# MCXN947_cm33_core0 register map
Vendor: nxp.com; File version: 1.0
CPU: CM33 r2p0, little endian, MPU, FPU, VTOR, 3 interrupt priority bits
Registers are 32-bit, read-write, reset 0x0 unless marked. A register's access mark holds for its fields unless they carry their own. Offsets are from the block's base; [hi:lo] are bit positions; {n}, {i} and the like mark numbered series; 'fields as' and 'values as' point back to an identical list.

## LPI2C0 — LPI2C
Base 0x40092800
Same registers: LPI2C1 0x40093800, LPI2C2 0x40094800, LPI2C3 0x40095800, LPI2C4 0x400B4800, LPI2C5 0x400B5800, LPI2C6 0x400B6800, LPI2C7 0x400B7800, LPI2C8 0x400B8800, LPI2C9 0x400B9800
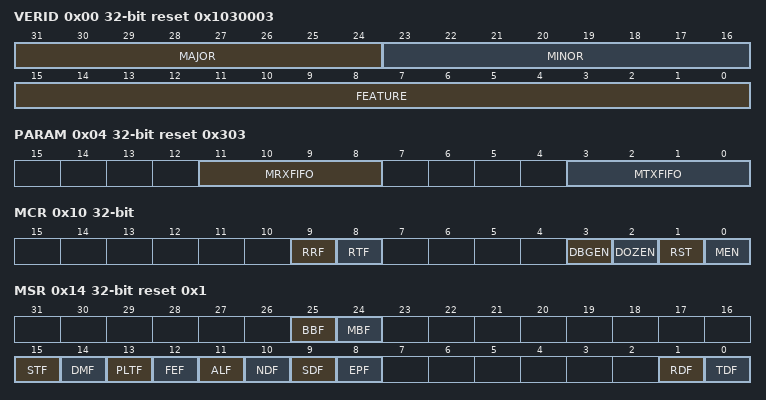
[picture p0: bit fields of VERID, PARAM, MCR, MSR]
0x00 VERID ro reset 0x1030003 — Version ID
  [31:24] MAJOR — Major Version Number
  [23:16] MINOR — Minor Version Number
  [15:0] FEATURE — Feature Specification Number
    2=MASTER_ONLY (Controller only, with standard feature set); 3=MASTER_AND_SLAVE (Controller and target, with standard feature set)
0x04 PARAM ro reset 0x303 — Parameter
  [11:8] MRXFIFO — Controller Receive FIFO Size
  [3:0] MTXFIFO — Controller Transmit FIFO Size
0x10 MCR — Controller Control
  [9] RRF — Reset Receive FIFO
    0=NO_EFFECT; 1=RESET (Receive FIFO is reset)
  [8] RTF — Reset Transmit FIFO
    0=NO_EFFECT; 1=RESET (Transmit FIFO is reset)
  [3] DBGEN — Debug Enable
    0=DISABLED (Controller is disabled in debug mode); 1=ENABLED (Controller is enabled in debug mode)
  [2] DOZEN — Doze mode enable
    0=ENABLED (Controller is enabled in doze mode); 1=DISABLED (Controller is disabled in doze mode)
  [1] RST — Software Reset
    0=NOT_RESET; 1=RESET
  [0] MEN — Controller Enable
    0=DISABLED; 1=ENABLED
0x14 MSR reset 0x1 — Controller Status
  [25] BBF ro — Bus Busy Flag
    0=IDLE; 1=BUSY
  [24] MBF ro — Controller Busy Flag
    0=IDLE; 1=BUSY
  [15] STF write-1-clears — START Flag
    0=NO_FLAG (START condition not detected.); 1=FLAG (START condition detected.)
  [14] DMF write-1-clears — Data Match Flag
    0=NO_FLAG (Have not received matching data); 1=FLAG (Have received matching data)
  [13] PLTF write-1-clears — Pin Low Timeout Flag
    0=NO_FLAG (Pin low timeout has not occurred or is disabled); 1=FLAG (Pin low timeout has occurred)
  [12] FEF write-1-clears — FIFO Error Flag
    0=NO_FLAG (No error); 1=FLAG (Controller sending or receiving data without a START condition)
  [11] ALF write-1-clears — Arbitration Lost Flag
    0=NO_FLAG (Controller has not lost arbitration); 1=FLAG (Controller has lost arbitration)
  [10] NDF write-1-clears — NACK Detect Flag
    0=NO_FLAG (Unexpected NACK was not detected); 1=FLAG (Unexpected NACK was detected)
  [9] SDF write-1-clears — STOP Detect Flag
    0=NO_FLAG (Controller has not generated a STOP condition); 1=FLAG (Controller has generated a STOP condition)
  [8] EPF write-1-clears — End Packet Flag
    0=NO_FLAG (Controller has not generated a STOP or Repeated START condition); 1=FLAG (Controller has generated a STOP or Repeated START condition)
  [1] RDF ro — Receive Data Flag
    0=DISABLED (Receive data is not ready); 1=ENABLED (Receive data is ready)
  [0] TDF ro — Transmit Data Flag
    0=DISABLED (Transmit data is not requested); 1=ENABLED (Transmit data is requested)
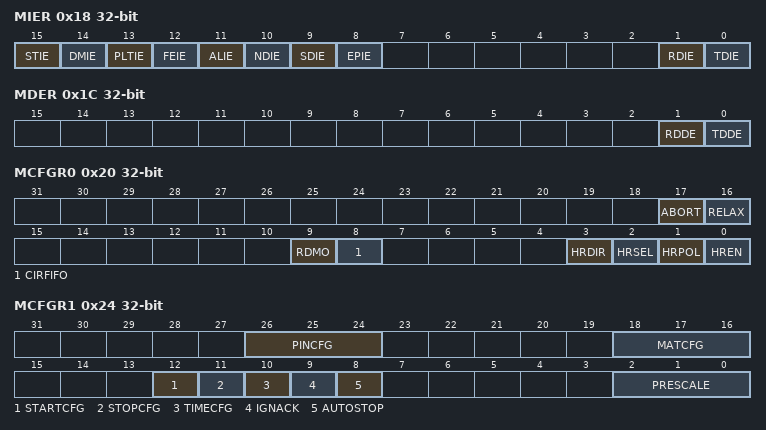
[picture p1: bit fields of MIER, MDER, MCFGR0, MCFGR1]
0x18 MIER — Controller Interrupt Enable
  [all] fields
    0=DISABLED; 1=ENABLED
  [15] STIE — START Interrupt Enable
  [14] DMIE — Data Match Interrupt Enable
  [13] PLTIE — Pin Low Timeout Interrupt Enable
  [12] FEIE — FIFO Error Interrupt Enable
  [11] ALIE — Arbitration Lost Interrupt Enable
  [10] NDIE — NACK Detect Interrupt Enable
  [9] SDIE — STOP Detect Interrupt Enable
  [8] EPIE — End Packet Interrupt Enable
  [1] RDIE — Receive Data Interrupt Enable
  [0] TDIE — Transmit Data Interrupt Enable
0x1C MDER — Controller DMA Enable
  [1] RDDE — Receive Data DMA Enable
    0=DISABLED (DMA request is disabled); 1=ENABLED (DMA request is enabled)
  [0] TDDE — Transmit Data DMA Enable
    values as RDDE
0x20 MCFGR0 — Controller Configuration 0
  [17] ABORT — Abort Transfer
    0=DISABLED (Normal transfer); 1=ENABLED (Abort existing transfer and do not start new transfer)
  [16] RELAX — Relaxed Mode
    0=NORMAL_TRANSFER; 1=RELAXED_TRANSFER
  [9] RDMO — Receive data match only
    0=DISABLED (Received data is stored in the receive FIFO); 1=ENABLED (Received data is discarded unless the Data Match Flag (MSR[DMF]) is 1.)
  [8] CIRFIFO — Circular FIFO enable
    0=DISABLED (Circular FIFO is disabled); 1=ENABLED (Circular FIFO is enabled)
  [3] HRDIR — Host request direction
    0=INPUT (HREQ pin is input (for LPI2C controller)); 1=OUTPUT (HREQ pin is output (for LPI2C target))
  [2] HRSEL — Host request select
    0=DISABLED (Host request input is pin HREQ); 1=ENABLED (Host request input is input trigger)
  [1] HRPOL — Host request polarity
    0=ACTIVE_LOW; 1=ACTIVE_HIGH
  [0] HREN — Host request enable
    0=DISABLED (Host request input is disabled); 1=ENABLED (Host request input is enabled)
0x24 MCFGR1 — Controller Configuration 1
  [26:24] PINCFG — Pin Configuration
    0=OPEN_DRAIN_2_PIN (Two-pin open drain mode); 1=OUTPUT_2_PIN_ONLY (Two-pin output only mode (ultra-fast mode)); 2=PUSH_PULL_2_PIN (Two-pin push-pull mode); 3=PUSH_PULL_4_PIN (Four-pin push-pull mode); 4=OPEN_DRAIN_2_PIN_W_LPI2C_SLAVE (Two-pin open drain mode with separate LPI2C target); 5=OUTPUT_2_PIN_ONLY_W_LPI2C_SLAVE (Two-pin output only mode (ultra-fast mode) with separate LPI2C target); 6=PUSH_PULL_2_PIN_W_LPI2C_SLAVE (Two-pin push-pull mode with separate LPI2C target); 7=PUSH_PULL_4_PIN_W_LPI2C_SLAVE (Four-pin push-pull mode (inverted outputs))
  [18:16] MATCFG — Match Configuration
    0=DISABLED (Match is disabled); 2=FIRST_DATA_WORD_EQUALS_MATCH0_OR_MATCH1 (Match is enabled (first data word equals MDMR[MATCH0] OR MDMR[MATCH1])); 3=ANY_DATA_WORD_EQUALS_MATCH0_OR_MATCH1 (Match is enabled (any data word equals MDMR[MATCH0] OR MDMR[MATCH1])); 4=FIRST_DATA_WORD_MATCH0_AND_SECOND_DATA_WORD_MATCH1 (Match is enabled (first data word equals MDMR[MATCH0] AND second data word equals MDMR[MATCH1)); 5=ANY_DATA_WORD_MATCH0_NEXT_DATA_WORD_MATCH1 (Match is enabled (any data word equals MDMR[MATCH0] AND next data word equals MDMR[MATCH1)); 6=FIRST_DATA_WORD_AND_MATCH1_EQUALS_MATCH0_AND_MATCH1 (Match is enabled (first data word AND MDMR[MATCH1] equals MDMR[MATCH0] AND MDMR[MATCH1])); 7=ANY_DATA_WORD_AND_MATCH1_EQUALS_MATCH0_AND_MATCH1 (Match is enabled (any data word AND MDMR[MATCH1] equals MDMR[MATCH0] AND MDMR[MATCH1]))
  [12] STARTCFG — START Configuration
    0=BOTH_I2C_AND_LPI2C_IDLE (MSR[STF] asserts on START condition provided both I2C bus and LPI2C controller are idle (that is, any non-repeated START condition initiated by any other controller on the bus but not the LPI2C controller).); 1=I2C_IDLE (MSR[STF] asserts on START condition provided I2C bus is idle (that is, any non-repeated START condition initiated by any controller on the bus including the LPI2C controller).)
  [11] STOPCFG — STOP Configuration
    0=ANY_STOP (MSR[SDF] asserts on any STOP condition generated by LPI2C controller.); 1=LAST_STOP (MSR[SDF] asserts on last STOP condition before LPI2C controller is idle (that is, the transmit FIFO is empty at the time of the STOP condition).)
  [10] TIMECFG — Timeout Configuration
    0=IF_SCL_LOW (MSR[PLTF] becomes 1 if SCL is low for longer than the configured timeout.); 1=IF_SCL_OR_SDA_LOW (MSR[PLTF] becomes 1 if either SCL or SDA is low for longer than the configured timeout.)
  [9] IGNACK — Ignore NACK
    0=DISABLED (No effect); 1=ENABLED (LPI2C controller treats a received NACK as if it (NACK) was an ACK and the NACK Detect Flag is never written 1.)
  [8] AUTOSTOP — Automatic STOP Generation
    0=DISABLED (No effect); 1=ENABLED (STOP condition is automatically generated when the transmit FIFO is empty and the LPI2C controller is busy)
  [2:0] PRESCALE — Prescaler
    0=DIVIDE_BY_1; 1=DIVIDE_BY_2; 2=DIVIDE_BY_4; 3=DIVIDE_BY_8; 4=DIVIDE_BY_16; 5=DIVIDE_BY_32; 6=DIVIDE_BY_64; 7=DIVIDE_BY_128
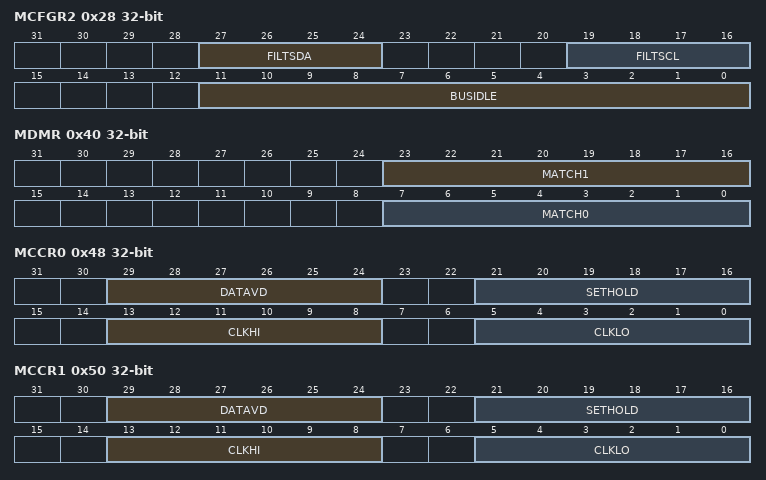
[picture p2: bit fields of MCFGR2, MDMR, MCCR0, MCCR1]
0x28 MCFGR2 — Controller Configuration 2
  [27:24] FILTSDA — Glitch Filter SDA
  [19:16] FILTSCL — Glitch Filter SCL
  [11:0] BUSIDLE — Bus Idle Timeout
0x2C MCFGR3 — Controller Configuration 3
  [19:8] PINLOW — Pin low timeout
0x40 MDMR — Controller Data Match
  [23:16] MATCH1 — Match 1 Value
  [7:0] MATCH0 — Match 0 Value
0x48 MCCR0 — Controller Clock Configuration 0
  [29:24] DATAVD — Data Valid Delay
  [21:16] SETHOLD — Setup Hold Delay
  [13:8] CLKHI — Clock High Period
  [5:0] CLKLO — Clock Low Period
0x50 MCCR1 — Controller Clock Configuration 1
  fields as MCCR0
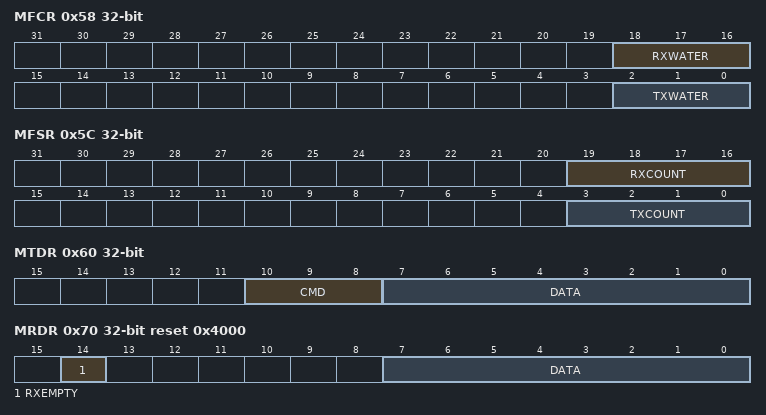
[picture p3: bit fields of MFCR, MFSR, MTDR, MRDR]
0x58 MFCR — Controller FIFO Control
  [18:16] RXWATER — Receive FIFO Watermark
  [2:0] TXWATER — Transmit FIFO Watermark
0x5C MFSR ro — Controller FIFO Status
  [19:16] RXCOUNT — Receive FIFO Count
  [3:0] TXCOUNT — Transmit FIFO Count
0x60 MTDR wo — Controller Transmit Data
  [10:8] CMD — Command Data
    0=TRANSMIT_DATA_7_THROUGH_0 (Transmit DATA[7:0]); 1=RECEIVE_DATA_7_THROUGH_0_PLUS_ONE (Receive (DATA[7:0] + 1) bytes); 2=GENERATE_STOP_CONDITION; 3=RECEIVE_AND_DISCARD_DATA_7_THROUGH_0_PLUS_ONE (Receive and discard (DATA[7:0] + 1) bytes); 4=GENERATE_START_AND_TRANSMIT_ADDRESS_IN_DATA_7_THROUGH_0 (Generate (repeated) START and transmit address in DATA[7:0]); 5=GENERATE_START_AND_TRANSMIT_ADDRESS_IN_DATA_7_THROUGH_0_EXPECT_NACK (Generate (repeated) START and transmit address in DATA[7:0]. This transfer expects a NACK to be returned.); 6=GENERATE_START_AND_TRANSMIT_ADDRESS_IN_DATA_7_THROUGH_0_USING_HIGH_SPEED_MODE (Generate (repeated) START and transmit address in DATA[7:0] using high-speed mode); 7=GENERATE_START_AND_TRANSMIT_ADDRESS_IN_DATA_7_THROUGH_0_USING_HIGH_SPEED_MODE_EXPECT_NACK (Generate (repeated) START and transmit address in DATA[7:0] using high-speed mode. This transfer expects a NACK to be returned.)
  [7:0] DATA — Transmit Data
0x70 MRDR ro reset 0x4000 — Controller Receive Data
  [14] RXEMPTY — Receive Empty
    0=NOT_EMPTY (Receive FIFO is not empty); 1=EMPTY (Receive FIFO is empty)
  [7:0] DATA — Receive Data
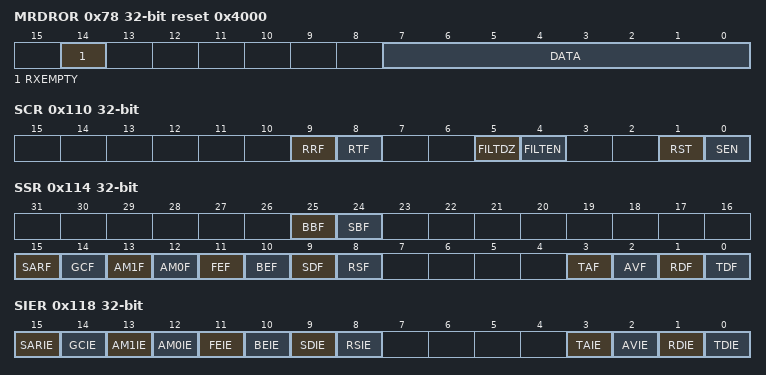
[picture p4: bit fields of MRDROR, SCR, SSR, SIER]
0x78 MRDROR ro reset 0x4000 — Controller Receive Data Read Only
  [14] RXEMPTY
    values as MRDR.RXEMPTY
  [7:0] DATA — Receive Data
0x110 SCR — Target Control
  [9] RRF — Reset Receive FIFO
    0=NO_EFFECT; 1=NOW_EMPTY (Receive Data Register is now empty.)
  [8] RTF — Reset transmit FIFO
    0=NO_EFFECT; 1=NOW_EMPTY (Transmit Data Register is now empty.)
  [5] FILTDZ — Filter doze enable
    0=FILTER_ENABLED (Filter remains enabled in Doze mode); 1=FILTER_DISABLED (Filter is disabled in Doze mode)
  [4] FILTEN — Filter enable
    0=DISABLE (Disable digital filter and output delay counter for target mode); 1=ENABLE (Enable digital filter and output delay counter for target mode)
  [1] RST — Software reset
    0=NOT_RESET (Target mode logic is not reset); 1=RESET (Target mode logic is reset)
  [0] SEN — Target Enable
    0=DISABLED (I2C Target mode is disabled); 1=ENABLED (I2C Target mode is enabled)
0x114 SSR — Target Status
  [25] BBF ro — Bus busy flag
    0=IDLE; 1=BUSY
  [24] SBF ro — Target busy flag
    0=IDLE; 1=BUSY
  [15] SARF ro — SMBus alert response flag
    0=NO_FLAG (SMBus alert response is disabled or not detected); 1=FLAG (SMBus alert response is enabled and detected)
  [14] GCF ro — General call flag
    0=NO_FLAG (Target has not detected the General Call Address or the General Call Address is disabled); 1=FLAG (Target has detected the General Call Address)
  [13] AM1F ro — Address match 1 flag
    0=NO_FLAG (ADDR1 or ADDR0/ADDR1 range matching address not received); 1=FLAG (ADDR1 or ADDR0/ADDR1 range matching address received)
  [12] AM0F ro — Address match 0 flag
    0=NO_FLAG (ADDR0 matching address not received); 1=FLAG (ADDR0 matching address received)
  [11] FEF write-1-clears — FIFO error flag
    0=NO_FLAG (FIFO underflow or overflow was not detected); 1=FLAG (FIFO underflow or overflow was detected)
  [10] BEF write-1-clears — Bit error flag
    0=NO_FLAG (Target has not detected a bit error); 1=FLAG (Target has detected a bit error)
  [9] SDF write-1-clears — STOP detect flag
    0=NO_FLAG (Target has not detected a STOP condition); 1=FLAG (Target has detected a STOP condition)
  [8] RSF write-1-clears — Repeated start flag
    0=NO_FLAG (Target has not detected a Repeated START condition); 1=FLAG (Target has detected a Repeated START condition)
  [3] TAF ro — Transmit ACK flag
    0=NOT_REQUIRED (Transmit ACK/NACK is not required); 1=REQUIRED (Transmit ACK/NACK is required)
  [2] AVF ro — Address valid flag
    0=NOT_VALID (Address Status Register is not valid); 1=VALID (Address Status Register is valid)
  [1] RDF ro — Receive data flag
    0=NOT_READY (Receive data is not ready); 1=READY (Receive data is ready)
  [0] TDF ro — Transmit data flag
    0=NO_FLAG (Transmit data not requested); 1=FLAG (Transmit data is requested)
0x118 SIER — Target interrupt enable
  [all] fields
    0=DISABLED; 1=ENABLED
  [15] SARIE — SMBus alert response interrupt enable
  [14] GCIE — General call interrupt enable
  [13] AM1IE — Address match 1 interrupt enable
  [12] AM0IE — Address match 0 interrupt enable
  [11] FEIE — FIFO error interrupt enable
  [10] BEIE — Bit error interrupt enable
  [9] SDIE — STOP detect interrupt enable
  [8] RSIE — Repeated start interrupt enable
  [3] TAIE — Transmit ACK interrupt enable
  [2] AVIE — Address valid interrupt enable
  [1] RDIE — Receive data interrupt enable
  [0] TDIE — Transmit data interrupt enable
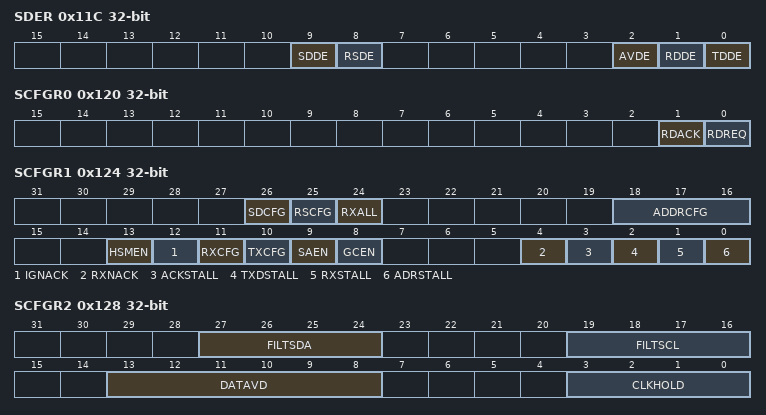
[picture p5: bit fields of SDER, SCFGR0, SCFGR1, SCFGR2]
0x11C SDER — Target DMA Enable
  [all] fields
    values as MDER.RDDE
  [9] SDDE — Stop detect DMA enable
  [8] RSDE — Repeated start DMA enable
  [2] AVDE — Address valid DMA enable
  [1] RDDE — Receive data DMA enable
  [0] TDDE — Transmit data DMA enable
0x120 SCFGR0 — Target Configuration 0
  [1] RDACK ro — Read Acknowledge
    0=NOT_ACKNOWLEDGED (Read Request not acknowledged); 1=ACKNOWLEDGED (Read Request acknowledged)
  [0] RDREQ — Read Request
    0=DISABLED; 1=ENABLED
0x124 SCFGR1 — Target Configuration 1
  [26] SDCFG — Stop Detect Configuration
    0=ANY_STOP_AFTER_ADDRESS_MATCH (Any STOP condition following an address match); 1=ANY_STOP (Any STOP condition)
  [25] RSCFG — Repeated start configuration
    0=ANY_REPEATED_START_AFTER_ADDRESS_MATCH (Any repeated START condition following an address match); 1=ANY_REPEATED_START (Any repeated START condition)
  [24] RXALL — Receive all
    0=DISABLED (Receive all disabled); 1=ENABLED (Receive all enabled)
  [18:16] ADDRCFG — Address configuration
    0=ADDRESS_MATCH0_7_BIT; 1=ADDRESS_MATCH0_10_BIT; 2=ADDRESS_MATCH0_7_BIT_OR_ADDRESS_MATCH1_7_BIT; 3=ADDRESS_MATCH0_10_BIT_OR_ADDRESS_MATCH1_10_BIT; 4=ADDRESS_MATCH0_7_BIT_OR_ADDRESS_MATCH1_10_BIT; 5=ADDRESS_MATCH0_10_BIT_OR_ADDRESS_MATCH1_7_BIT; 6=FROM_ADDRESS_MATCH0_7_BIT_TO_ADDRESS_MATCH1_7_BIT; 7=FROM_ADDRESS_MATCH0_10_BIT_TO_ADDRESS_MATCH1_10_BIT
  [13] HSMEN — High-speed mode enable
    0=DISABLED; 1=ENABLED
  [12] IGNACK — Ignore NACK
    0=ENDS_TRANSFER_ON_NACK (Target ends transfer when NACK is detected); 1=DOES_NOT_END_TRANSFER_ON_NACK (Target does not end transfer when NACK detected)
  [11] RXCFG — Receive Data Configuration
    0=RETURNS_RECEIVED_DATA_AND_CLEARS_RX_DATA_FLAG (Reading the Receive Data register returns received data and writes 0 to the Receive Data flag.); 1=WHEN_ADDRESS_VALID_FLAG_SET_RETURNS_ADDRESS_STATUS_AND_CLEARS_ADDRESS_VALID_FLAG (Reading the Receive Data register when the Address Valid flag (SSR[AVF]) is 1, returns the Address Status register and writes 0 to SSR[AVF]. Reading the Receive Data register when SSR[AVF] is 0, returns received data and writes 0 to the Receive Data flag (MSR[RDF]).)
  [10] TXCFG — Transmit flag configuration
    0=ASSERTS_DURING_SLAVE_TRANSMIT_TRANSFER_WHEN_TX_DATA_EMPTY (MSR[TDF] becomes 1 only during a target-transmit transfer when the Transmit Data register is empty); 1=ASSERTS_WHEN_TX_DATA_EMPTY (MSR[TDF] becomes 1 whenever the Transmit Data register is empty)
  [9] SAEN — SMBus alert enable
    0=DISABLE (Disables match on SMBus Alert); 1=ENABLE (Enables match on SMBus Alert)
  [8] GCEN — General call enable
    0=DISABLED (General Call address is disabled); 1=ENABLED (General Call address is enabled)
  [4] RXNACK — Receive NACK
    0=SET_BY_TXNACK (ACK/NACK always written 1 by TXNACK); 1=ALWAYS_GENERATED_ON_ADDRESS_OR_RECEIVE_DATA_OVERRUN (NACK always generated on address overrun or receive data overrun, otherwise ACK/NACK is written 1 by TXNACK.)
  [3] ACKSTALL — ACK SCL stall
    0=DISABLED; 1=ENABLED
  [2] TXDSTALL — Transmit data SCL stall
    0=DISABLED; 1=ENABLED
  [1] RXSTALL — RX SCL stall
    0=DISABLED; 1=ENABLED
  [0] ADRSTALL — Address SCL stall
    0=DISABLED; 1=ENABLED
0x128 SCFGR2 — Target Configuration 2
  [27:24] FILTSDA — Glitch filter SDA
  [19:16] FILTSCL — Glitch filter SCL
  [13:8] DATAVD — Data valid delay
  [3:0] CLKHOLD — Clock hold time
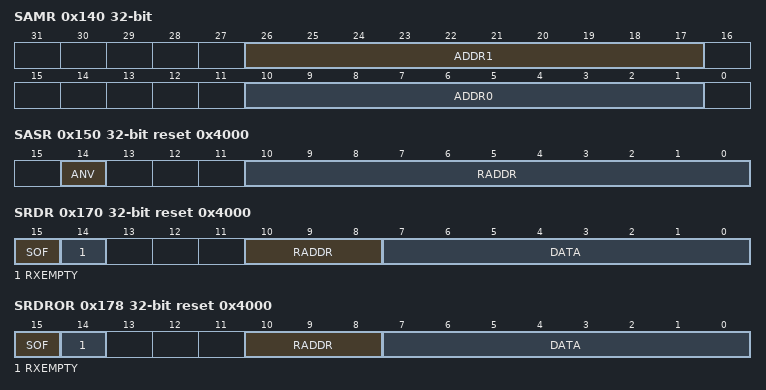
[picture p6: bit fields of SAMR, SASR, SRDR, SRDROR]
0x140 SAMR — Target Address Match
  [26:17] ADDR1 — Address 1 value
  [10:1] ADDR0 — Address 0 value
0x150 SASR ro reset 0x4000 — Target Address Status
  [14] ANV — Address not valid
    0=VALID (Received Address (RADDR) is valid); 1=NOT_VALID (Received Address (RADDR) is not valid)
  [10:0] RADDR — Received Address
0x154 STAR — Target Transmit ACK
  [0] TXNACK — Transmit NACK
    0=TRANSMIT_ACK (Write a Transmit ACK for each received word); 1=TRANSMIT_NACK (Write a Transmit NACK for each received word)
0x160 STDR wo — Target Transmit Data
  [7:0] DATA — Transmit data
0x170 SRDR ro reset 0x4000 — Target Receive Data
  [15] SOF — Start of frame
    0=NOT_FIRST_DATA_WORD (Not the first data word since a (repeated) START or STOP condition); 1=FIRST_DATA_WORD (Is the first data word since a (repeated) START or STOP condition)
  [14] RXEMPTY — Receive empty
    0=NOT_EMPTY (The Receive Data Register is not empty); 1=EMPTY (The Receive Data Register is empty)
  [10:8] RADDR — Received address
  [7:0] DATA — Receive data
0x178 SRDROR ro reset 0x4000 — Target Receive Data Read Only
  [15] SOF — Start of frame
    0=NOT_FIRST_DATA_WORD (Is not the first data word since a (repeated) START or STOP condition); 1=FIRST_DATA_WORD (Is the first data word since a (repeated) START or STOP condition)
  [14] RXEMPTY — Receive empty
    values as SRDR.RXEMPTY
  [10:8] RADDR — Received address
  [7:0] DATA — Receive data
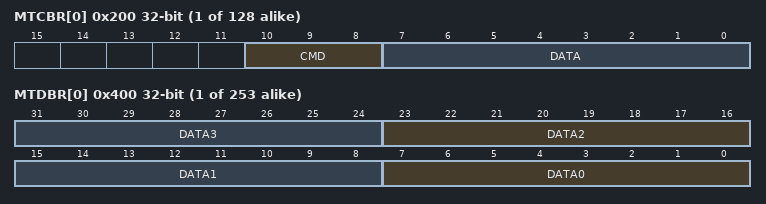
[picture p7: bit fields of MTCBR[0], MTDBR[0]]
{0x200+4i} MTCBR[{i}] (i=0..127) wo — Controller Transmit Command Burst
  [10:8] CMD — Command
  [7:0] DATA
{0x400+4i} MTDBR[{i}] (i=0..252) wo — Transmit Data Burst
  [8n+7:8n] DATA{n} (n=0..3) — Data
